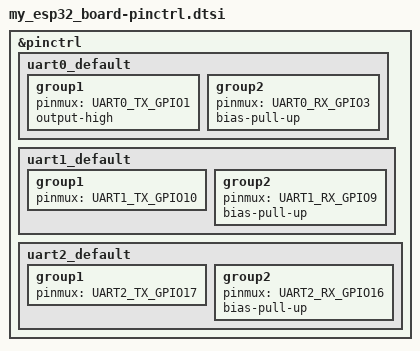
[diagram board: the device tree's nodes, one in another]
#include <zephyr/dt-bindings/pinctrl/esp-pinctrl-common.h>
#include <dt-bindings/pinctrl/esp32-pinctrl.h>
#include <zephyr/dt-bindings/pinctrl/esp32-gpio-sigmap.h>

&pinctrl {

	uart0_default: uart0_default {
		group1 {
			pinmux = <UART0_TX_GPIO1>;
			output-high;
		};

		group2 {
			pinmux = <UART0_RX_GPIO3>;
			bias-pull-up;
		};
	};

	uart1_default: uart1_default {
		group1 {
			pinmux = <UART1_TX_GPIO10>;
		};

		group2 {
			pinmux = <UART1_RX_GPIO9>;
			bias-pull-up;
		};
	};

	uart2_default: uart2_default {
		group1 {
			pinmux = <UART2_TX_GPIO17>;
		};

		group2 {
			pinmux = <UART2_RX_GPIO16>;
			bias-pull-up;
		};
	};
};
